AUTOSAR XML (schema 4-3-0)
package /BMW/Platform/IntegrationSample/SwComponentTypes
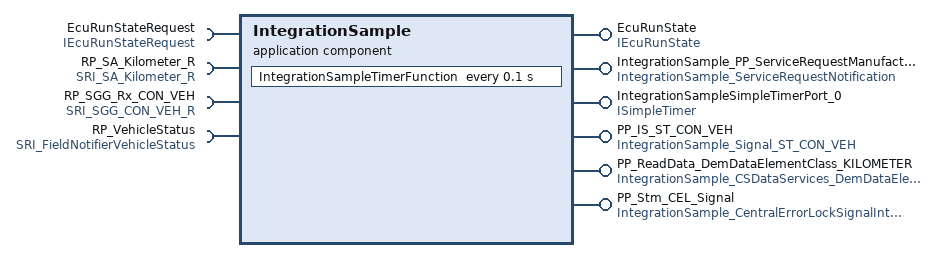
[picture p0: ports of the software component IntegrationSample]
  application sw component type IntegrationSample
    6 x provide port:
      EcuRunState: mode-switch-sender-com-spec{enhanced-mode-api=false, mode-group=EcuRunStateMode, queue-length=1}, provided-interface=IEcuRunState
      IntegrationSample_PP_ServiceRequestManufacturerNotificationPort: provided-com-specs=[{operation=Confirmation, queue-length=1}, {operation=Indication, queue-length=1}], provided-interface=IntegrationSample_ServiceRequestNotification
      IntegrationSampleSimpleTimerPort_0: mode-switch-sender-com-spec{enhanced-mode-api=false, mode-group=SimpleTimerMode, queue-length=2}, provided-interface=ISimpleTimer
      PP_IS_ST_CON_VEH: nonqueued-sender-com-spec{data-element=VehicleState, init-value=PP_IS_ST_CON_VEH_InvalidValue:15}, provided-interface=IntegrationSample_Signal_ST_CON_VEH
      PP_ReadData_DemDataElementClass_KILOMETER: server-com-spec{operation=ReadData, queue-length=1}, provided-interface=IntegrationSample_CSDataServices_DemDataElementClass_KILOMETER
      PP_Stm_CEL_Signal: nonqueued-sender-com-spec=data-element=centralErrorLock, provided-interface=IntegrationSample_CentralErrorLockSignalInterface
    4 x require port:
      EcuRunStateRequest: nonqueued-receiver-com-spec{data-element=IntegrationSample_EcuRunStateRequestMode, filter=data-filter-type=ALWAYS, init-value=IntegrationSample_STARTUP}, required-interface=IEcuRunStateRequest
      RP_SA_Kilometer_R: nonqueued-receiver-com-spec{data-element=Notifier, alive-timeout=20, enable-update=true, filter=data-filter-type=ALWAYS, init-value={short-label=value_CrBrLeft1Dot6777215E7CrBrRight, fields=value_1Dot6777215E7:16777215}}, required-interface=SRI_SA_Kilometer_R
      RP_SGG_Rx_CON_VEH: nonqueued-receiver-com-spec{data-element=IntegrationSample_IDT_CON_VEH, alive-timeout=0.5, enable-update=true, filter=data-filter-type=ALWAYS, init-value={short-label=IntegrationSample_InitValues_SGG_Rx_CON_VEH, fields=[IV_SGG_Rx_CON_VEH_ST_CON_VEH:0xF, IV_SGG_Rx_CON_VEH_CTR_FKTN_PRTNT:0xFFFFFFFF, IV_SGG_Rx_CON_VEH_CTR_BS_PRTNT:0xF]}}, required-interface=SRI_SGG_CON_VEH_R
      RP_VehicleStatus: nonqueued-receiver-com-spec{data-element=Notifier, alive-timeout=21, enable-update=true, filter=data-filter-type=ALWAYS, init-value=fields=[0, 0]}, required-interface=SRI_FieldNotifierVehicleStatus
    behavior IB_IntegrationSample: data-type-mapping=[IntegrationSampleModemappingSimpleTimerMode, IntegrationSampleModemappingEcuRunState]
      exclusive area EXA_IntegrationSample
      operation invoked event IntegrationSample_Event_ManufacturerConfirmation: start-on-event=IntegrationSample_Runnable_ManufacturerConfirmation, operation=IntegrationSample_PP_ServiceRequestManufacturerNotificationPort.Confirmation
      operation invoked event IntegrationSample_Event_ManufacturerIndication: start-on-event=IntegrationSample_Runnable_ManufacturerIndication, operation=IntegrationSample_PP_ServiceRequestManufacturerNotificationPort.Indication
      timing event IntegrationSample_SimpleTimer_TimingEvent: start-on-event=IntegrationSampleTimerFunction, period=0.1
      data received event EcuRunState: start-on-event=R_IntegrationSample_EcuRunStateHandler, data=EcuRunStateRequest.IntegrationSample_EcuRunStateRequestMode
      operation invoked event OIE_ReadDataMILE_KM: start-on-event=R_ReadDataMILE_KM, operation=PP_ReadData_DemDataElementClass_KILOMETER.ReadData
      data received event DRE_SGG_Rx_CON_VEH: start-on-event=R_Receive_SGG_Rx_CON_VEH, data=RP_SGG_Rx_CON_VEH.IntegrationSample_IDT_CON_VEH
      data received event DRE_SIG_MILE_KM_816_R: start-on-event=R_Receive_SIG_MILE_KM_816_R, data=RP_SA_Kilometer_R.Notifier
      data received event DRE_VehicleStatus: start-on-event=R_Receive_VehicleStatus, data=RP_VehicleStatus.Notifier
      data receive error event DRET_SGG_Rx_CON_VEH: start-on-event=R_Timeout_SGG_Rx_CON_VEH, data=RP_SGG_Rx_CON_VEH.IntegrationSample_IDT_CON_VEH
      data receive error event DRET_VehicleStatus: start-on-event=R_Timeout_VehicleStatus, data=RP_VehicleStatus.Notifier
      10 x runnable:
        IntegrationSample_Runnable_ManufacturerConfirmation: can-be-invoked-concurrently=true, symbol=IntegrationSample_ManufacturerConfirmation
        IntegrationSample_Runnable_ManufacturerIndication: can-be-invoked-concurrently=true, symbol=IntegrationSample_ManufacturerIndication
        IntegrationSampleTimerFunction: symbol=R_IntegrationSample_TimerFunction
          mode switch point MSP_SampleTimer_Mode_0: mode-group=IntegrationSampleSimpleTimerPort_0.SimpleTimerMode
        R_IntegrationSample_EcuRunStateHandler: mode-access-point=EcuRunState.EcuRunStateMode, symbol=IntegrationSample_EcuRunStateHandler
          data-read-access:
            access DRA_requestMode: accessed-variable=EcuRunStateRequest.IntegrationSample_EcuRunStateRequestMode
          mode switch point MSP_Mode: mode-group=EcuRunState.EcuRunStateMode
        R_ReadDataMILE_KM: can-enter-exclusive-area=EXA_IntegrationSample, can-be-invoked-concurrently=true
        R_Receive_SGG_Rx_CON_VEH: can-enter-exclusive-area=EXA_IntegrationSample, can-be-invoked-concurrently=true
          data-receive-point-by-arguments:
            access IntegrationSample_DRP0_SGG_Rx_CON_VEH: accessed-variable=RP_SGG_Rx_CON_VEH.IntegrationSample_IDT_CON_VEH
          data-send-points:
            access VariableAccess_ST_CON_VEH: accessed-variable=PP_IS_ST_CON_VEH.VehicleState
        R_Receive_SIG_MILE_KM_816_R: can-enter-exclusive-area=EXA_IntegrationSample, can-be-invoked-concurrently=true, symbol=Runnable_IS_Receive_SIG_MILE_KM_816_R
          data-receive-point-by-arguments:
            access IntegrationSample_VariableAccess_SIG_MILE_KM_816_R: accessed-variable=RP_SA_Kilometer_R.Notifier
        R_Receive_VehicleStatus: can-enter-exclusive-area=EXA_IntegrationSample, can-be-invoked-concurrently=true, symbol=Runnable_IS_R_Receive_VehicleStatus
          data-receive-point-by-arguments:
            access IntegrationSample_VariableAccess_VehicleStatus: accessed-variable=RP_VehicleStatus.Notifier
          data-send-points:
            access VariableAccess_centralErrorLock: accessed-variable=PP_Stm_CEL_Signal.centralErrorLock
        R_Timeout_SGG_Rx_CON_VEH: can-be-invoked-concurrently=true, symbol=Runnable_IS_R_Timeout_SGG_Rx_CON_VEH
        R_Timeout_VehicleStatus: can-be-invoked-concurrently=true, symbol=Runnable_IS_R_Timeout_VehicleStatus
  swc implementation IMPL_IntegrationSample: behavior=IB_IntegrationSample
    code-descriptors:
      code Default: artifact-descriptors=autosar-engineering-object={short-label=Default, category=SWSRC}
